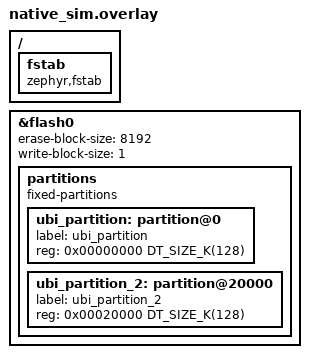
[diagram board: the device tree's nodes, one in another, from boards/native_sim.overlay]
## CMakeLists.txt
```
cmake_minimum_required(VERSION 3.20.0)

find_package(Zephyr REQUIRED HINTS $ENV{ZEPHYR_BASE})

project(ubi_tests)

target_compile_options(app PRIVATE
    -Werror
    -Wextra
    -Wshadow
    -Wdouble-promotion
    -Wformat=2
    -Wnull-dereference
    -Wunused
    -Wno-unused-parameter
)
target_compile_definitions(app PRIVATE _POSIX_C_SOURCE=200809L)

target_sources(app PRIVATE
               src/plain/tests_ubi_device.c
               src/plain/tests_ubi_volumes.c
               src/plain/tests_ubi_map_unmap.c
               src/plain/tests_ubi_write_read.c
               src/plain/tests_ubi_partial_write.c
               src/plain/tests_ubi_erase.c
               src/plain/tests_ubi_mixed.c
               src/plain/tests_ubi_error_handling.c
               src/plain/tests_ubi_error_handling_leb.c
               src/plain/tests_ubi_error_handling_volume.c
               src/plain/tests_ubi_boundary.c
               src/plain/tests_ubi_recovery.c
               src/plain/tests_ubi_recovery_reserved.c
               src/plain/tests_ubi_fault_injection.c
               src/plain/tests_ubi_io_faults.c
               src/plain/tests_ubi_init_errors.c
               src/plain/tests_ubi_init_errors_geometry.c
               src/plain/tests_ubi_hil_smoke.c
               src/plain/tests_ubi_concurrency.c
               src/plain/tests_ubi_erased_val.c
               src/plain/tests_ubi_mutation_gate.c
               src/plain/tests_ubi_vol_id_watermark.c
               src/plain/tests_ubi_io_defensive.c)

if(CONFIG_FLASH_SIMULATOR)
    target_sources(app PRIVATE src/plain/tests_ubi_stress.c
                               src/plain/tests_ubi_torture.c
                               src/plain/tests_ubi_stress_longrun.c)
endif()

target_include_directories(app PRIVATE src/common)
target_include_directories(app PRIVATE src/secure)
target_include_directories(app PRIVATE ../lib/src/plain)

target_sources(app PRIVATE src/common/arrays.c)

if(CONFIG_UBI_SECURE)
    target_include_directories(app PRIVATE ../lib/src/secure)
    target_include_directories(app PRIVATE ../lib/src/plain)
    target_sources(app PRIVATE src/secure/tests_ubi_secure_api.c
                               src/secure/tests_ubi_secure_attach.c
                               src/secure/tests_ubi_secure_device.c
                               src/secure/tests_ubi_secure_volumes.c
                               src/secure/tests_ubi_secure_write_read.c
                               src/secure/tests_ubi_secure_map_unmap.c
                               src/secure/tests_ubi_secure_erase.c
                               src/secure/tests_ubi_secure_mixed.c
                               src/secure/tests_ubi_secure_tamper.c
                               src/secure/tests_ubi_secure_runtime_policy.c
                               src/secure/tests_ubi_secure_runtime_policy_budgets.c
                               src/secure/tests_ubi_secure_recovery.c
                               src/secure/tests_ubi_secure_forensic.c
                               src/secure/tests_ubi_secure_error_handling.c
                               src/secure/tests_ubi_secure_error_handling_volume.c
                               src/secure/tests_ubi_secure_error_handling_leb.c
                               src/secure/tests_ubi_secure_fault_injection.c
                               src/secure/tests_ubi_secure_mutation_gate.c
                               src/secure/tests_ubi_secure_vol_id_watermark.c
                               src/secure/tests_ubi_secure_crypto_faults.c
                               src/secure/tests_ubi_secure_coverage.c
                               src/secure/tests_ubi_secure_defensive.c
                               src/secure/tests_ubi_secure_defensive_io_hooks.c
                               src/secure/tests_ubi_secure_defensive_reserved.c
                               src/secure/tests_ubi_secure_replay.c
                               src/secure/tests_ubi_secure_anchor.c)
    if(CONFIG_FLASH_SIMULATOR)
        target_sources(app PRIVATE src/secure/tests_ubi_secure_concurrency.c
                                   src/secure/tests_ubi_secure_stress.c)
    endif()
    # Coexistence test requires a second flash partition labelled
    # `ubi_partition_2` in the active devicetree (provided by native_sim
    # overlays, absent on HW boards).
    dt_nodelabel(ubi_part2_path NODELABEL "ubi_partition_2")
    if(DEFINED ubi_part2_path)
        target_sources(app PRIVATE src/secure/tests_ubi_secure_coexistence.c)
    endif()
    if(CONFIG_UBI_SECURE_LEB_CHUNKED)
        target_sources(app PRIVATE src/secure/tests_ubi_secure_chunked.c)
    endif()
endif()
```

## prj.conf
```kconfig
CONFIG_ZTEST=y

# Memory settings
CONFIG_HEAP_MEM_POOL_SIZE=16384
CONFIG_ZTEST_STACK_SIZE=32768

# Shell settings
CONFIG_SHELL=y
CONFIG_SHELL_VT100_COLORS=n

# Flash settings
CONFIG_FLASH=y
CONFIG_FLASH_MAP=y
CONFIG_FLASH_PAGE_LAYOUT=y
CONFIG_MPU_ALLOW_FLASH_WRITE=y

# CRC settings
CONFIG_CRC=y

# Debug and assert settings
CONFIG_DEBUG_OPTIMIZATIONS=y
CONFIG_ASSERT=y

# Log settings
CONFIG_LOG=y

# Assertion settings
CONFIG_ASSERT=y
CONFIG_ASSERT_ON_ERRORS=y

# Stats settings (required for flash simulator thresholds)
CONFIG_STATS=y
CONFIG_STATS_NAMES=y

# Heap settings
CONFIG_SYS_HEAP_RUNTIME_STATS=y

# UBI settings
CONFIG_UBI_ENABLE=y
CONFIG_UBI_LOG_LEVEL_ERR=y
CONFIG_UBI_TEST_API_ENABLE=y
CONFIG_UBI_TEST_FAULT_INJECTION=y
```

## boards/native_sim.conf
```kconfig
CONFIG_FLASH_SIMULATOR=y
CONFIG_FLASH_SIMULATOR_DOUBLE_WRITES=y
CONFIG_FLASH_SIMULATOR_EXPLICIT_ERASE=y
CONFIG_FLASH_SIMULATOR_STATS=y
```

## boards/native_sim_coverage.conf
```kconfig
# Coverage-specific configuration for native_sim
# Use with: west build -b native_sim -- -DOVERLAY_CONFIG="boards/native_sim_coverage.conf"

CONFIG_COVERAGE=y
CONFIG_COVERAGE_GCOV=y
CONFIG_COVERAGE_DUMP=y
```

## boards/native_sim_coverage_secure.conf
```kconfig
# Secure backend + coverage configuration for native_sim
CONFIG_COVERAGE=y
CONFIG_COVERAGE_GCOV=y
CONFIG_COVERAGE_DUMP=y

# Platform entropy (native_sim uses fake entropy for testing)
CONFIG_ENTROPY_GENERATOR=y
CONFIG_TEST_RANDOM_GENERATOR=y
CONFIG_ENTROPY_INIT_PRIORITY=30
CONFIG_MBEDTLS_ENTROPY_POLL_ZEPHYR=y

# PSA Crypto prerequisites (PSA_WANT_* auto-selected by UBI_SECURE)
CONFIG_MBEDTLS=y
CONFIG_MBEDTLS_PSA_CRYPTO_C=y

# UBI secure backend
CONFIG_UBI_SECURE=y
CONFIG_UBI_SECURE_TEST_FAULT_INJECTION=y

# Two concurrent devices needed by the plain+secure coexistence test.
CONFIG_UBI_MAX_NR_OF_DEVICES=2

# Lower budget thresholds for integration tests.
# Must match native_sim_secure.conf so the runtime_policy budget tests
# (which use BUDGET_HEADROOM=5) trip at the expected counter values.
CONFIG_UBI_SECURE_LEB_WRITE_BUDGET=100
CONFIG_UBI_SECURE_LEB_TOTAL_AUTH_BYTES_BUDGET=10000
CONFIG_UBI_SECURE_METADATA_COUNTER_BUDGET=100
CONFIG_UBI_SECURE_METADATA_TOTAL_AUTH_BYTES_BUDGET=10000
```

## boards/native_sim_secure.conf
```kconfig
# Secure backend configuration for native_sim
CONFIG_FLASH_SIMULATOR=y
CONFIG_FLASH_SIMULATOR_DOUBLE_WRITES=y
CONFIG_FLASH_SIMULATOR_EXPLICIT_ERASE=y
CONFIG_FLASH_SIMULATOR_STATS=y

# Platform entropy (native_sim uses fake entropy for testing)
CONFIG_ENTROPY_GENERATOR=y
CONFIG_TEST_RANDOM_GENERATOR=y
CONFIG_ENTROPY_INIT_PRIORITY=30
CONFIG_MBEDTLS_ENTROPY_POLL_ZEPHYR=y

# PSA Crypto prerequisites (PSA_WANT_* auto-selected by UBI_SECURE)
CONFIG_MBEDTLS=y
CONFIG_MBEDTLS_PSA_CRYPTO_C=y

# UBI secure backend
CONFIG_UBI_SECURE=y
CONFIG_UBI_SECURE_TEST_FAULT_INJECTION=y

# Two concurrent devices needed by the plain+secure coexistence test.
CONFIG_UBI_MAX_NR_OF_DEVICES=2

# Lower budget thresholds for integration tests (§14.5 budget test).
CONFIG_UBI_SECURE_LEB_WRITE_BUDGET=100
CONFIG_UBI_SECURE_LEB_TOTAL_AUTH_BYTES_BUDGET=10000
CONFIG_UBI_SECURE_METADATA_COUNTER_BUDGET=100
CONFIG_UBI_SECURE_METADATA_TOTAL_AUTH_BYTES_BUDGET=10000
```

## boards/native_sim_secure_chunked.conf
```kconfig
# Secure backend configuration for native_sim with chunked LEB mode
CONFIG_FLASH_SIMULATOR=y
CONFIG_FLASH_SIMULATOR_DOUBLE_WRITES=y
CONFIG_FLASH_SIMULATOR_EXPLICIT_ERASE=y
CONFIG_FLASH_SIMULATOR_STATS=y

# Platform entropy (native_sim uses fake entropy for testing)
CONFIG_ENTROPY_GENERATOR=y
CONFIG_TEST_RANDOM_GENERATOR=y
CONFIG_ENTROPY_INIT_PRIORITY=30
CONFIG_MBEDTLS_ENTROPY_POLL_ZEPHYR=y

# PSA Crypto prerequisites (PSA_WANT_* auto-selected by UBI_SECURE)
CONFIG_MBEDTLS=y
CONFIG_MBEDTLS_PSA_CRYPTO_C=y

# UBI secure backend
CONFIG_UBI_SECURE=y
CONFIG_UBI_SECURE_TEST_FAULT_INJECTION=y

# Two concurrent devices needed by the plain+secure coexistence test.
CONFIG_UBI_MAX_NR_OF_DEVICES=2

# Lower budget thresholds for integration tests (§14.5 budget test).
CONFIG_UBI_SECURE_LEB_WRITE_BUDGET=100
CONFIG_UBI_SECURE_LEB_TOTAL_AUTH_BYTES_BUDGET=10000
CONFIG_UBI_SECURE_METADATA_COUNTER_BUDGET=100
CONFIG_UBI_SECURE_METADATA_TOTAL_AUTH_BYTES_BUDGET=10000

# Chunked LEB mode with 256-byte chunks (§7.8, §15.3)
CONFIG_UBI_SECURE_LEB_CHUNKED=y
CONFIG_UBI_SECURE_LEB_CHUNK_SIZE=256
```

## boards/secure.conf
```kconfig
# Secure backend configuration for cross-build targets.
# Cross-builds are compile-only (no execution), so a test entropy source
# is acceptable where hardware entropy requires IPC (e.g. nRF5340 rng_hci).
CONFIG_TEST_RANDOM_GENERATOR=y
CONFIG_ENTROPY_GENERATOR=y
CONFIG_MBEDTLS=y
CONFIG_MBEDTLS_PSA_CRYPTO_C=y
CONFIG_MBEDTLS_ENTROPY_POLL_ZEPHYR=y
CONFIG_UBI_SECURE=y
CONFIG_UBI_SECURE_TEST_FAULT_INJECTION=y

# Lower budget thresholds for integration tests (§14.5 budget test).
CONFIG_UBI_SECURE_LEB_WRITE_BUDGET=100
CONFIG_UBI_SECURE_LEB_TOTAL_AUTH_BYTES_BUDGET=10000
CONFIG_UBI_SECURE_METADATA_COUNTER_BUDGET=100
CONFIG_UBI_SECURE_METADATA_TOTAL_AUTH_BYTES_BUDGET=10000

# PSA Crypto (mbedTLS) requires more stack on Cortex-M than the default 1 KiB.
CONFIG_MAIN_STACK_SIZE=8192
```

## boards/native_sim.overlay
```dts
/ {
	fstab {
		compatible = "zephyr,fstab";
	};
};

&flash0 {
	/* Default native_sim geometry: 8 KB erase pages, 1-byte write granularity.
	 * 16 PEBs × 8 KB = 128 KB partition (14 data + 2 reserved).
	 * For MCU-specific geometries use native_sim_nrf5340.overlay or
	 * native_sim_stm32u5.overlay via -DDTC_OVERLAY_FILE.
	 */
	erase-block-size = <8192>;
	write-block-size = <1>;

	partitions {
		compatible = "fixed-partitions";
		#address-cells = <1>;
		#size-cells = <1>;

		ubi_partition: partition@0 {
			label = "ubi_partition";
			reg = <0x00000000 DT_SIZE_K(128)>;
		};

		ubi_partition_2: partition@20000 {
			label = "ubi_partition_2";
			reg = <0x00020000 DT_SIZE_K(128)>;
		};
	};
};
```

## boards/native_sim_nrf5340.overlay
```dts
/ {
	fstab {
		compatible = "zephyr,fstab";
	};
};

&flash0 {
	/* nRF5340 geometry: 4 KB erase pages, 4-byte write alignment.
	 * 16 PEBs × 4 KB = 64 KB partition (14 data + 2 reserved).
	 */
	erase-block-size = <4096>;
	write-block-size = <4>;

	partitions {
		compatible = "fixed-partitions";
		#address-cells = <1>;
		#size-cells = <1>;

		ubi_partition: partition@0 {
			label = "ubi_partition";
			reg = <0x00000000 DT_SIZE_K(64)>;
		};

		ubi_partition_2: partition@10000 {
			label = "ubi_partition_2";
			reg = <0x00010000 DT_SIZE_K(64)>;
		};
	};
};
```

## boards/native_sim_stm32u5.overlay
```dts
/ {
	fstab {
		compatible = "zephyr,fstab";
	};
};

&flash0 {
	/* STM32U5 geometry: 8 KB erase pages, 16-byte write alignment.
	 * 16 PEBs × 8 KB = 128 KB partition (14 data + 2 reserved).
	 */
	erase-block-size = <8192>;
	write-block-size = <16>;

	partitions {
		compatible = "fixed-partitions";
		#address-cells = <1>;
		#size-cells = <1>;

		ubi_partition: partition@0 {
			label = "ubi_partition";
			reg = <0x00000000 DT_SIZE_K(128)>;
		};

		ubi_partition_2: partition@20000 {
			label = "ubi_partition_2";
			reg = <0x00020000 DT_SIZE_K(128)>;
		};
	};
};
```

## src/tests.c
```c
/**
 * \file    tests.c
 * \author  Kamil Kielbasa
 * \brief   Hardware tests for Unsorted Block Images (UBI) implementation.
 * \version 0.1
 * \date    2025-07-25
 *
 * \copyright Copyright (c) 2025
 *
 */

/* Include files ----------------------------------------------------------- */

/* UBI header: */
#include <ubi.h>

/* Zephyr headers: */
#include <zephyr/ztest.h>
#include <zephyr/device.h>
#include <zephyr/drivers/flash.h>
#include <zephyr/kernel.h>
#include <zephyr/storage/flash_map.h>
#include <zephyr/sys/printk.h>
#include <zephyr/toolchain/common.h>
#include <zephyr/sys/sys_heap.h>

#include <stdio.h>
#include <stdint.h>
#include <stddef.h>

/* Module defines ---------------------------------------------------------- */

#define UBI_PARTITION_NAME ubi_partition
#define UBI_PARTITION_DEVICE FIXED_PARTITION_DEVICE(UBI_PARTITION_NAME)
#define UBI_PARTITION_OFFSET FIXED_PARTITION_OFFSET(UBI_PARTITION_NAME)
#define UBI_PARTITION_SIZE FIXED_PARTITION_SIZE(UBI_PARTITION_NAME)

/* Module types and type definitiones -------------------------------------- */
/* Module interface variables and constants -------------------------------- */
/* Static variables and constants ------------------------------------------ */

static struct mem_tech_device mtd = { 0 };

#if defined(CONFIG_SYS_HEAP_RUNTIME_STATS)
extern struct sys_heap _system_heap;
#endif

static const uint8_t rdata[256] = {
	0x00, 0x01, 0x02, 0x03, 0x04, 0x05, 0x06, 0x07, 0x08, 0x09, 0x0A, 0x0B, 0x0C, 0x0D, 0x0E,
	0x0F, 0x10, 0x11, 0x12, 0x13, 0x14, 0x15, 0x16, 0x17, 0x18, 0x19, 0x1A, 0x1B, 0x1C, 0x1D,
	0x1E, 0x1F, 0x20, 0x21, 0x22, 0x23, 0x24, 0x25, 0x26, 0x27, 0x28, 0x29, 0x2A, 0x2B, 0x2C,
	0x2D, 0x2E, 0x2F, 0x30, 0x31, 0x32, 0x33, 0x34, 0x35, 0x36, 0x37, 0x38, 0x39, 0x3A, 0x3B,
	0x3C, 0x3D, 0x3E, 0x3F, 0x40, 0x41, 0x42, 0x43, 0x44, 0x45, 0x46, 0x47, 0x48, 0x49, 0x4A,
	0x4B, 0x4C, 0x4D, 0x4E, 0x4F, 0x50, 0x51, 0x52, 0x53, 0x54, 0x55, 0x56, 0x57, 0x58, 0x59,
	0x5A, 0x5B, 0x5C, 0x5D, 0x5E, 0x5F, 0x60, 0x61, 0x62, 0x63, 0x64, 0x65, 0x66, 0x67, 0x68,
	0x69, 0x6A, 0x6B, 0x6C, 0x6D, 0x6E, 0x6F, 0x70, 0x71, 0x72, 0x73, 0x74, 0x75, 0x76, 0x77,
	0x78, 0x79, 0x7A, 0x7B, 0x7C, 0x7D, 0x7E, 0x7F, 0x80, 0x81, 0x82, 0x83, 0x84, 0x85, 0x86,
	0x87, 0x88, 0x89, 0x8A, 0x8B, 0x8C, 0x8D, 0x8E, 0x8F, 0x90, 0x91, 0x92, 0x93, 0x94, 0x95,
	0x96, 0x97, 0x98, 0x99, 0x9A, 0x9B, 0x9C, 0x9D, 0x9E, 0x9F, 0xA0, 0xA1, 0xA2, 0xA3, 0xA4,
	0xA5, 0xA6, 0xA7, 0xA8, 0xA9, 0xAA, 0xAB, 0xAC, 0xAD, 0xAE, 0xAF, 0xB0, 0xB1, 0xB2, 0xB3,
	0xB4, 0xB5, 0xB6, 0xB7, 0xB8, 0xB9, 0xBA, 0xBB, 0xBC, 0xBD, 0xBE, 0xBF, 0xC0, 0xC1, 0xC2,
	0xC3, 0xC4, 0xC5, 0xC6, 0xC7, 0xC8, 0xC9, 0xCA, 0xCB, 0xCC, 0xCD, 0xCE, 0xCF, 0xD0, 0xD1,
	0xD2, 0xD3, 0xD4, 0xD5, 0xD6, 0xD7, 0xD8, 0xD9, 0xDA, 0xDB, 0xDC, 0xDD, 0xDE, 0xDF, 0xE0,
	0xE1, 0xE2, 0xE3, 0xE4, 0xE5, 0xE6, 0xE7, 0xE8, 0xE9, 0xEA, 0xEB, 0xEC, 0xED, 0xEE, 0xEF,
	0xF0, 0xF1, 0xF2, 0xF3, 0xF4, 0xF5, 0xF6, 0xF7, 0xF8, 0xF9, 0xFA, 0xFB, 0xFC, 0xFD, 0xFE,
	0xFF
};

/* Static function declarations -------------------------------------------- */

static void *ztest_suite_setup(void);
static void ztest_suite_after(void *ctx);

static void ztest_testcase_before(void *ctx);
static void ztest_testcase_teardown(void *ctx);

/* Static function definitions --------------------------------------------- */

static void *ztest_suite_setup(void)
{
	const struct device *flash_dev = UBI_PARTITION_DEVICE;
	zassert_true(device_is_ready(flash_dev));

	struct flash_pages_info page_info = { 0 };
	zassert_ok(flash_get_page_info_by_offs(flash_dev, 0, &page_info));

	const size_t write_block_size = flash_get_write_block_size(flash_dev);
	const size_t erase_block_size = page_info.size;

	mtd.dev = flash_dev;
	mtd.p_off = UBI_PARTITION_OFFSET;
	mtd.p_size = UBI_PARTITION_SIZE;
	mtd.eb_size = erase_block_size;
	mtd.wb_size = write_block_size;

	return NULL;
}

static void ztest_suite_after(void *ctx)
{
	(void)ctx;

	return;
}

static void ztest_testcase_before(void *ctx)
{
	(void)ctx;

	zassert_ok(flash_erase(UBI_PARTITION_DEVICE, UBI_PARTITION_OFFSET, UBI_PARTITION_SIZE));

	return;
}

static void ztest_testcase_teardown(void *ctx)
{
	(void)ctx;
	return;
}

/* Module interface function definitions ----------------------------------- */

ZTEST_SUITE(ubi, NULL, ztest_suite_setup, ztest_testcase_before, ztest_testcase_teardown,
	    ztest_suite_after);

ZTEST(ubi, init_deinit)
{
	zassert_ok(ubi_init(&mtd));

	struct ubi_device_info dev_info = { 0 };
	zassert_ok(ubi_info(&dev_info, NULL));

	zassert_equal(0, dev_info.alloc_pebs);
	zassert_equal(0, dev_info.dirty_pebs);
	zassert_equal(0, dev_info.bad_pebs);
	zassert_not_equal(0, dev_info.free_pebs);

	const size_t nr_of_pebs = mtd.p_size / mtd.eb_size;
	zassert_not_equal(0, dev_info.leb_count);
	zassert_not_equal(nr_of_pebs, dev_info.leb_count);

	zassert_not_equal(0, dev_info.leb_size);
	zassert_not_equal(mtd.eb_size, dev_info.leb_size);

	zassert_ok(ubi_deinit());
}

ZTEST(ubi, multiple_init_deinit)
{
	zassert_ok(ubi_init(&mtd));
	zassert_ok(ubi_deinit());
	zassert_ok(ubi_init(&mtd));
	zassert_ok(ubi_deinit());
	zassert_ok(ubi_init(&mtd));
	zassert_ok(ubi_deinit());
}

ZTEST(ubi, init_deinit_with_heap_checks)
{
	struct sys_memory_stats stat_before_init = { 0 };
	zassert_ok(sys_heap_runtime_stats_get(&_system_heap, &stat_before_init));

	zassert_ok(ubi_init(&mtd));

	struct sys_memory_stats stat_after_init = { 0 };
	zassert_ok(sys_heap_runtime_stats_get(&_system_heap, &stat_after_init));

	zassert_ok(ubi_deinit());

	struct sys_memory_stats stat_after_deinit = { 0 };
	zassert_ok(sys_heap_runtime_stats_get(&_system_heap, &stat_after_deinit));

	zassert_equal(stat_before_init.free_bytes, stat_after_deinit.free_bytes);
	zassert_equal(stat_before_init.allocated_bytes, stat_after_deinit.allocated_bytes);
	zassert_equal(stat_before_init.max_allocated_bytes, stat_after_deinit.max_allocated_bytes);

	zassert_not_equal(stat_after_init.free_bytes, stat_after_deinit.free_bytes);
	zassert_not_equal(stat_after_init.allocated_bytes, stat_after_deinit.allocated_bytes);
	zassert_equal(stat_after_init.max_allocated_bytes, stat_after_deinit.max_allocated_bytes);
}

ZTEST(ubi, map_and_unmap)
{
	zassert_ok(ubi_init(&mtd));

	struct ubi_device_info dev_info = { 0 };
	zassert_ok(ubi_info(&dev_info, NULL));

	for (size_t lnum = 0; lnum < dev_info.leb_count; ++lnum) {
		zassert_ok(ubi_leb_map(lnum));
	}

	zassert_ok(ubi_info(&dev_info, NULL));
	zassert_equal(dev_info.leb_count, dev_info.alloc_pebs);
	zassert_equal(0, dev_info.free_pebs);
	zassert_equal(0, dev_info.dirty_pebs);
	zassert_equal(0, dev_info.bad_pebs);

	for (size_t lnum = 0; lnum < dev_info.leb_count; ++lnum) {
		zassert_ok(ubi_leb_unmap(lnum));
	}

	zassert_ok(ubi_info(&dev_info, NULL));
	zassert_equal(0, dev_info.alloc_pebs);
	zassert_equal(0, dev_info.free_pebs);
	zassert_equal(dev_info.leb_count, dev_info.dirty_pebs);
	zassert_equal(0, dev_info.bad_pebs);

	zassert_ok(ubi_deinit());
}

ZTEST(ubi, map_unmap_erase_map)
{
	zassert_ok(ubi_init(&mtd));

	struct ubi_device_info dev_info = { 0 };
	zassert_ok(ubi_info(&dev_info, NULL));

	for (size_t lnum = 0; lnum < dev_info.leb_count; ++lnum) {
		zassert_ok(ubi_leb_map(lnum));
	}

	zassert_ok(ubi_info(&dev_info, NULL));
	zassert_equal(dev_info.leb_count, dev_info.alloc_pebs);
	zassert_equal(0, dev_info.free_pebs);
	zassert_equal(0, dev_info.dirty_pebs);
	zassert_equal(0, dev_info.bad_pebs);

	for (size_t lnum = 0; lnum < dev_info.leb_count; ++lnum) {
		zassert_ok(ubi_leb_unmap(lnum));
	}

	zassert_ok(ubi_info(&dev_info, NULL));
	zassert_equal(0, dev_info.alloc_pebs);
	zassert_equal(0, dev_info.free_pebs);
	zassert_equal(dev_info.leb_count, dev_info.dirty_pebs);
	zassert_equal(0, dev_info.bad_pebs);

	while (dev_info.dirty_pebs > 0) {
		zassert_ok(ubi_peb_erase());
		zassert_ok(ubi_info(&dev_info, NULL));
	}

	zassert_ok(ubi_info(&dev_info, NULL));
	zassert_equal(0, dev_info.alloc_pebs);
	zassert_equal(dev_info.leb_count, dev_info.free_pebs);
	zassert_equal(0, dev_info.dirty_pebs);
	zassert_equal(0, dev_info.bad_pebs);

	for (size_t lnum = 0; lnum < dev_info.leb_count; ++lnum) {
		zassert_ok(ubi_leb_map(lnum));
	}

	zassert_ok(ubi_info(&dev_info, NULL));
	zassert_equal(dev_info.leb_count, dev_info.alloc_pebs);
	zassert_equal(0, dev_info.free_pebs);
	zassert_equal(0, dev_info.dirty_pebs);
	zassert_equal(0, dev_info.bad_pebs);

	zassert_ok(ubi_deinit());
}

ZTEST(ubi, write_read_small_buffer)
{
	zassert_ok(ubi_init(&mtd));

	const uint8_t buf[32] = { 0x00, 0x11, 0x22, 0x33, 0x44, 0x55, 0x66, 0x77, 0x88, 0x99, 0xAA,
				  0xBB, 0xCC, 0xDD, 0xEE, 0xFF, 0x1A, 0x2B, 0x3C, 0x4D, 0x5E, 0x6F,
				  0x70, 0x81, 0x92, 0xA3, 0xB4, 0xC5, 0xD6, 0xE7, 0xF8, 0x09 };

	const size_t lnum = 0;
	zassert_ok(ubi_leb_write(lnum, buf, ARRAY_SIZE(buf)));

	const size_t offset = 0;

	size_t len = 0;
	uint8_t output[ARRAY_SIZE(buf)] = { 0 };
	zassert_ok(ubi_leb_read(lnum, output, offset, &len));

	zassert_equal(ARRAY_SIZE(buf), len);
	zassert_mem_equal(buf, output, ARRAY_SIZE(buf), "Memory blocks are not equal");

	zassert_ok(ubi_deinit());
}

ZTEST(ubi, write_read_max_buffer)
{
	zassert_ok(ubi_init(&mtd));

	struct ubi_device_info dev_info = { 0 };
	zassert_ok(ubi_info(&dev_info, NULL));

	uint8_t buf[dev_info.leb_size];
	memset(buf, 0, sizeof(buf));

	for (size_t i = 0; i < ARRAY_SIZE(buf); ++i)
		buf[i] = (uint8_t)i;

	const size_t lnum = dev_info.leb_count - 1;
	zassert_ok(ubi_leb_write(lnum, buf, ARRAY_SIZE(buf)));

	const size_t offset = 0;

	size_t len = 0;
	uint8_t output[dev_info.leb_size];
	memset(output, 0, sizeof(output));
	zassert_ok(ubi_leb_read(lnum, output, offset, &len));

	zassert_equal(ARRAY_SIZE(buf), len);
	zassert_mem_equal(buf, output, ARRAY_SIZE(buf), "Memory blocks are not equal");

	zassert_ok(ubi_deinit());
}

ZTEST(ubi, full_scenario)
{
	zassert_ok(ubi_init(&mtd));

	struct ubi_device_info dev_info = { 0 };
	zassert_ok(ubi_info(&dev_info, NULL));

	const size_t map_lnums[] = { 0, 1, 2, 3, 4, 5 };

	for (size_t i = 0; i < ARRAY_SIZE(map_lnums); ++i) {
		zassert_ok(ubi_leb_map(map_lnums[i]));

		bool is_map = false;
		zassert_ok(ubi_leb_is_mapped(map_lnums[i], &is_map));
		zassert_true(is_map);
	}

	const size_t wr_lnums[] = { dev_info.leb_count / 2 + 0, dev_info.leb_count / 2 + 1,
				    dev_info.leb_count / 2 + 2, dev_info.leb_count / 2 + 3 };
	const size_t wr_sizes[] = { 32, 64, 128, 256 };

	for (size_t i = 0; i < ARRAY_SIZE(wr_lnums); ++i) {
		zassert_ok(ubi_leb_write(wr_lnums[i], rdata, wr_sizes[i]));

		bool is_map = false;
		zassert_ok(ubi_leb_is_mapped(wr_lnums[i], &is_map));
		zassert_true(is_map);
	}

	zassert_ok(ubi_info(&dev_info, NULL));
	zassert_equal(dev_info.alloc_pebs, ARRAY_SIZE(map_lnums) + ARRAY_SIZE(wr_lnums));
	zassert_equal(dev_info.free_pebs,
		      dev_info.leb_count - ARRAY_SIZE(map_lnums) - ARRAY_SIZE(wr_lnums));
	zassert_equal(0, dev_info.dirty_pebs);
	zassert_equal(0, dev_info.bad_pebs);

	for (size_t i = 0; i < ARRAY_SIZE(map_lnums); ++i) {
		const size_t offset = 0;
		uint8_t buf[ARRAY_SIZE(rdata)] = { 0 };
		size_t len = 0;

		zassert_ok(ubi_leb_read(map_lnums[i], buf, offset, &len));
		zassert_equal(0, len);
	}

	for (size_t i = 0; i < ARRAY_SIZE(wr_lnums); ++i) {
		const size_t offset = 0;
		uint8_t buf[ARRAY_SIZE(rdata)] = { 0 };
		size_t len = 0;

		zassert_ok(ubi_leb_read(wr_lnums[i], buf, offset, &len));
		zassert_equal(wr_sizes[i], len);
		zassert_mem_equal(rdata, buf, len, "Memory blocks are not equal");
	}

	zassert_ok(ubi_deinit());
}

ZTEST(ubi, flash_equal_weariness)
{
	size_t reserved_pebs = 0;
	struct ubi_device_info dev_info = { 0 };
	struct ubi_flash_info flash_info = { 0 };

	zassert_ok(ubi_init(&mtd));

	const size_t cycles = 5;
	const size_t cycle_exp_peb_ec[] = { 0, 1, 2, 3, 4 };
	const size_t cycle_exp_ec_avr[] = { 0, 1, 2, 3, 4 };

	/* Cycle 1: */
	for (size_t cycle = 0; cycle < cycles; ++cycle) {
		zassert_ok(ubi_info(&dev_info, &flash_info));
		zassert_equal(cycle_exp_ec_avr[cycle], flash_info.ec_average);
		zassert_not_equal(0, flash_info.peb_count);

		for (size_t pnum = 0; pnum < flash_info.peb_count; ++pnum) {
			if (flash_info.peb_init[pnum]) {
				zassert_equal(cycle_exp_peb_ec[cycle], flash_info.peb_ec[pnum]);
			} else {
				reserved_pebs += 1;
			}
		}
		zassert_equal(1, reserved_pebs);

		k_free(flash_info.peb_init);
		k_free(flash_info.peb_ec);

		for (size_t lnum = 0; lnum < dev_info.leb_count; ++lnum) {
			zassert_ok(ubi_leb_map(lnum));
			zassert_ok(ubi_leb_unmap(lnum));
			zassert_ok(ubi_peb_erase());
		}

		memset(&dev_info, 0, sizeof(dev_info));
		memset(&flash_info, 0, sizeof(flash_info));
		reserved_pebs = 0;
	}

	zassert_ok(ubi_deinit());
}
```

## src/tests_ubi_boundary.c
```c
/**
 * \file    tests_ubi_boundary.c
 *
 * \author  Kamil Kielbasa
 *
 * \brief   Tests for UBI LEB boundary and capacity edge cases.
 *
 * \version 0.9
 * \date    2026-03-26
 *
 * \copyright Copyright (c) 2025
 *
 */

/* Include files ------------------------------------------------------------------------------- */

/* UBI header: */
#include <ubi.h>

/* Zephyr headers: */
#include <zephyr/ztest.h>
#include <zephyr/device.h>
#include <zephyr/drivers/flash.h>
#include <zephyr/kernel.h>
#include <zephyr/storage/flash_map.h>
#include <zephyr/sys/printk.h>
#include <zephyr/toolchain/common.h>
#include <zephyr/sys/sys_heap.h>

#include <stdio.h>
#include <stdint.h>
#include <stddef.h>
#include <string.h>

/* Module defines ------------------------------------------------------------------------------ */

#define UBI_PARTITION_NAME ubi_partition
#define UBI_PARTITION_DEVICE FIXED_PARTITION_DEVICE(UBI_PARTITION_NAME)
#define UBI_PARTITION_OFFSET FIXED_PARTITION_OFFSET(UBI_PARTITION_NAME)
#define UBI_PARTITION_SIZE FIXED_PARTITION_SIZE(UBI_PARTITION_NAME)

/* UBI header sizes (must match lib/src/ubi_io.h). */
#define UBI_EC_HDR_SIZE (16)
#define UBI_VID_HDR_SIZE (32)

/* Module types and type definitiones ---------------------------------------------------------- */
/* Module interface variables and constants ---------------------------------------------------- */
/* Static variables and constants -------------------------------------------------------------- */

static struct ubi_mtd mtd = { 0 };

/* Static function declarations ---------------------------------------------------------------- */

static void *ztest_suite_setup(void);
static void ztest_suite_after(void *ctx);

static void ztest_testcase_before(void *ctx);
static void ztest_testcase_teardown(void *ctx);

/* Static function definitions ----------------------------------------------------------------- */

static void *ztest_suite_setup(void)
{
	const struct device *flash_dev = UBI_PARTITION_DEVICE;
	zassert_true(device_is_ready(flash_dev));

	struct flash_pages_info page_info = { 0 };
	zassert_ok(flash_get_page_info_by_offs(flash_dev, 0, &page_info));

	const size_t write_block_size = flash_get_write_block_size(flash_dev);
	const size_t erase_block_size = page_info.size;

	mtd.partition_id = FIXED_PARTITION_ID(UBI_PARTITION_NAME);
	mtd.erase_block_size = erase_block_size;
	mtd.write_block_size = write_block_size;

	return NULL;
}

static void ztest_suite_after(void *ctx)
{
	(void)ctx;

	return;
}

static void ztest_testcase_before(void *ctx)
{
	(void)ctx;

	zassert_ok(flash_erase(UBI_PARTITION_DEVICE, UBI_PARTITION_OFFSET, UBI_PARTITION_SIZE));

	return;
}

static void ztest_testcase_teardown(void *ctx)
{
	(void)ctx;
	return;
}

/* Module interface function definitions ------------------------------------------------------- */

ZTEST_SUITE(ubi_boundary, NULL, ztest_suite_setup, ztest_testcase_before, ztest_testcase_teardown,
	    ztest_suite_after);

/**
 * \brief Verify that writing exactly the maximum LEB data capacity succeeds.
 *
 * \details Scenario: Create a dynamic volume with 2 LEBs. Calculate the maximum
 *          writable data per LEB (erase_block_size - EC_HDR - VID_HDR = 8144 bytes
 *          on 8 KB erase blocks). Fill a buffer with a 0xAB pattern of exactly that
 *          size and write it to LEB 0.
 *
 * \expect The write succeeds. The stored size equals the maximum data capacity.
 *         Reading back the full LEB returns identical data byte-for-byte.
 */
ZTEST(ubi_boundary, write_max_leb_data)
{
	struct ubi_device *ubi = NULL;
	zassert_ok(ubi_device_init(&mtd, &ubi));

	const struct ubi_volume_config cfg = {
		.name = "max_leb",
		.type = UBI_VOLUME_TYPE_DYNAMIC,
		.leb_count = 2,
	};
	int vol_id;
	zassert_ok(ubi_volume_create(ubi, &cfg, &vol_id));

	const size_t max_data = mtd.erase_block_size - UBI_EC_HDR_SIZE - UBI_VID_HDR_SIZE;
	uint8_t *wbuf = k_malloc(max_data);
	zassert_not_null(wbuf);
	memset(wbuf, 0xAB, max_data);

	/* Write exactly max capacity — must succeed. */
	zassert_ok(ubi_leb_write(ubi, vol_id, 0, wbuf, max_data));
	k_free(wbuf);

	/* Read back and verify. */
	uint8_t *rbuf = k_malloc(max_data);
	zassert_not_null(rbuf);
	memset(rbuf, 0, max_data);

	size_t stored_size = 0;
	zassert_ok(ubi_leb_get_size(ubi, vol_id, 0, &stored_size));
	zassert_equal(stored_size, max_data);

	zassert_ok(ubi_leb_read(ubi, vol_id, 0, 0, rbuf, max_data));

	/* Verify all bytes are 0xAB */
	bool all_match = true;
	for (size_t i = 0; i < max_data; i++) {
		if (rbuf[i] != 0xAB) {
			all_match = false;
			break;
		}
	}
	zassert_true(all_match, "Read-back data mismatch");

	k_free(rbuf);
	zassert_ok(ubi_device_deinit(ubi));
}

/**
 * \brief Verify that writing one byte beyond the maximum LEB capacity is rejected.
 *
 * \details Scenario: Create a dynamic volume with 2 LEBs. Attempt to write
 *          (max_data + 1) bytes to a single LEB, which exceeds the available
 *          data area after the EC and VID headers.
 *
 * \expect ubi_leb_write() returns -ENOSPC. No data is written to the LEB.
 */
ZTEST(ubi_boundary, write_exceeds_leb_capacity)
{
	struct ubi_device *ubi = NULL;
	zassert_ok(ubi_device_init(&mtd, &ubi));

	const struct ubi_volume_config cfg = {
		.name = "exceed",
		.type = UBI_VOLUME_TYPE_DYNAMIC,
		.leb_count = 2,
	};
	int vol_id;
	zassert_ok(ubi_volume_create(ubi, &cfg, &vol_id));

	const size_t max_data = mtd.erase_block_size - UBI_EC_HDR_SIZE - UBI_VID_HDR_SIZE;
	uint8_t *wbuf = k_malloc(max_data + 1);
	zassert_not_null(wbuf);
	memset(wbuf, 0xCD, max_data + 1);

	/* One byte over capacity — must fail with -ENOSPC. */
	zassert_equal(-ENOSPC, ubi_leb_write(ubi, vol_id, 0, wbuf, max_data + 1));

	k_free(wbuf);
	zassert_ok(ubi_device_deinit(ubi));
}

/**
 * \brief Verify reading at the exact end boundary of stored data.
 *
 * \details Scenario: Write an 8-byte pattern to LEB 0. Issue a read with
 *          offset=4 and size=4, so that offset + size equals exactly the
 *          stored data size (8 bytes). This tests the boundary condition
 *          where the read touches the last byte of stored data.
 *
 * \expect ubi_leb_read() succeeds. The 4 returned bytes match the tail
 *         portion (bytes 4..7) of the original pattern.
 */
ZTEST(ubi_boundary, read_at_exact_boundary)
{
	struct ubi_device *ubi = NULL;
	zassert_ok(ubi_device_init(&mtd, &ubi));

	const struct ubi_volume_config cfg = {
		.name = "rbound",
		.type = UBI_VOLUME_TYPE_DYNAMIC,
		.leb_count = 2,
	};
	int vol_id;
	zassert_ok(ubi_volume_create(ubi, &cfg, &vol_id));

	const uint8_t pattern[] = { 0x11, 0x22, 0x33, 0x44, 0x55, 0x66, 0x77, 0x88 };
	zassert_ok(ubi_leb_write(ubi, vol_id, 0, pattern, sizeof(pattern)));

	/* Read last 4 bytes using offset — offset(4) + size(4) = 8 = stored_size. */
	uint8_t tail[4] = { 0 };
	zassert_ok(ubi_leb_read(ubi, vol_id, 0, 4, tail, sizeof(tail)));
	zassert_mem_equal(tail, &pattern[4], sizeof(tail));

	zassert_ok(ubi_device_deinit(ubi));
}

/**
 * \brief Verify writes at and just above the write-block alignment boundary.
 *
 * \details Scenario: Create a dynamic volume with 2 LEBs. Write exactly 16 bytes
 *          (aligned to WRITE_BLOCK_SIZE_ALIGNMENT) to LEB 0, and 17 bytes (one
 *          byte over alignment, triggering the partial-block padding path in
 *          ubi_leb_data_write()) to LEB 1. Read both back.
 *
 * \expect Both writes succeed. Read-back data matches the original patterns
 *         exactly, confirming that the padding logic does not corrupt data.
 */
ZTEST(ubi_boundary, write_alignment_boundary)
{
	struct ubi_device *ubi = NULL;
	zassert_ok(ubi_device_init(&mtd, &ubi));

	const struct ubi_volume_config cfg = {
		.name = "align",
		.type = UBI_VOLUME_TYPE_DYNAMIC,
		.leb_count = 2,
	};
	int vol_id;
	zassert_ok(ubi_volume_create(ubi, &cfg, &vol_id));

	/* Write exactly 16 bytes (aligned) */
	uint8_t aligned[16];
	memset(aligned, 0xAA, sizeof(aligned));
	zassert_ok(ubi_leb_write(ubi, vol_id, 0, aligned, sizeof(aligned)));

	uint8_t rbuf[16] = { 0 };
	zassert_ok(ubi_leb_read(ubi, vol_id, 0, 0, rbuf, sizeof(rbuf)));
	zassert_mem_equal(aligned, rbuf, sizeof(aligned));

	/* Write 17 bytes (1 byte over alignment — exercises padding path) */
	uint8_t unaligned[17];
	memset(unaligned, 0xBB, sizeof(unaligned));
	zassert_ok(ubi_leb_write(ubi, vol_id, 1, unaligned, sizeof(unaligned)));

	uint8_t rbuf2[17] = { 0 };
	zassert_ok(ubi_leb_read(ubi, vol_id, 1, 0, rbuf2, sizeof(rbuf2)));
	zassert_mem_equal(unaligned, rbuf2, sizeof(unaligned));

	zassert_ok(ubi_device_deinit(ubi));
}

/**
 * \brief Verify writes smaller than the write-block alignment (< 16 bytes).
 *
 * \details Scenario: Create a dynamic volume with 2 LEBs. Write 1 byte (the
 *          minimum possible write) to LEB 0 and 15 bytes (just under the 16-byte
 *          alignment boundary) to LEB 1. These sizes exercise the small-buffer
 *          padding path in ubi_leb_data_write() where the data is smaller than
 *          a single alignment unit.
 *
 * \expect Both writes succeed. ubi_leb_get_size() returns the exact logical
 *         size (1 and 15). Read-back data matches the original bytes.
 */
ZTEST(ubi_boundary, write_sub_alignment)
{
	struct ubi_device *ubi = NULL;
	zassert_ok(ubi_device_init(&mtd, &ubi));

	const struct ubi_volume_config cfg = {
		.name = "sub",
		.type = UBI_VOLUME_TYPE_DYNAMIC,
		.leb_count = 2,
	};
	int vol_id;
	zassert_ok(ubi_volume_create(ubi, &cfg, &vol_id));

	/* Write 1 byte — minimum possible write */
	const uint8_t one = 0xFF;
	zassert_ok(ubi_leb_write(ubi, vol_id, 0, &one, 1));

	size_t stored = 0;
	zassert_ok(ubi_leb_get_size(ubi, vol_id, 0, &stored));
	zassert_equal(stored, 1);

	uint8_t rb = 0;
	zassert_ok(ubi_leb_read(ubi, vol_id, 0, 0, &rb, 1));
	zassert_equal(rb, 0xFF);

	/* Write 15 bytes — just under alignment */
	uint8_t buf15[15];
	memset(buf15, 0xCC, sizeof(buf15));
	zassert_ok(ubi_leb_write(ubi, vol_id, 1, buf15, sizeof(buf15)));

	uint8_t rbuf15[15] = { 0 };
	zassert_ok(ubi_leb_read(ubi, vol_id, 1, 0, rbuf15, sizeof(rbuf15)));
	zassert_mem_equal(buf15, rbuf15, sizeof(buf15));

	zassert_ok(ubi_device_deinit(ubi));
}

/* --- Sequence number monotonicity across remount --- */

/* Raw VID header for direct flash reads. */
struct raw_vid_hdr {
	uint32_t magic;
	uint8_t version;
	uint8_t padding[3];
	uint32_t lnum;
	uint32_t vol_id;
	uint64_t sqnum;
	uint32_t data_size;
	uint32_t hdr_crc;
};

/**
 * \brief Verify that global_sqnum is strictly monotonic after device re-init.
 *
 * \details Scenario: init → create volume → write LEB 0 → deinit →
 *          init → write LEB 1 → read raw VID headers of both LEBs.
 *
 * \expect The second write's sqnum is strictly greater than the first's.
 */
ZTEST(ubi_boundary, sqnum_monotonic_across_remount)
{
	/* First session: write LEB 0. */
	struct ubi_device *ubi = NULL;
	zassert_ok(ubi_device_init(&mtd, &ubi));

	const struct ubi_volume_config cfg = {
		.name = "sqn",
		.type = UBI_VOLUME_TYPE_DYNAMIC,
		.leb_count = 2,
	};
	int vol_id;
	zassert_ok(ubi_volume_create(ubi, &cfg, &vol_id));

	const uint8_t data1[] = { 0xAA };
	zassert_ok(ubi_leb_write(ubi, vol_id, 0, data1, sizeof(data1)));

	zassert_ok(ubi_device_deinit(ubi));

	/* Second session: write LEB 1. */
	ubi = NULL;
	zassert_ok(ubi_device_init(&mtd, &ubi));

	/* Re-read vol_id after remount. */
	struct ubi_volume_config cfg2;
	size_t alloc;
	zassert_ok(ubi_volume_get_info(ubi, vol_id, &cfg2, &alloc));

	const uint8_t data2[] = { 0xBB };
	zassert_ok(ubi_leb_write(ubi, vol_id, 1, data2, sizeof(data2)));

	/* Read raw VID headers to compare sqnums. */
	const struct flash_area *fa = NULL;
	zassert_ok(flash_area_open(FIXED_PARTITION_ID(ubi_partition), &fa));

	const size_t nr_of_pebs = fa->fa_size / mtd.erase_block_size;
	uint64_t sqnum_leb0 = 0;
	uint64_t sqnum_leb1 = 0;

	for (size_t p = CONFIG_UBI_DEV_HDR_NR_OF_RES_PEBS; p < nr_of_pebs; ++p) {
		struct raw_vid_hdr vid;
		zassert_ok(flash_area_read(fa, (p * mtd.erase_block_size) + UBI_EC_HDR_SIZE, &vid,
					   sizeof(vid)));

		if (vid.magic != 0x55424921)
			continue;

		if (vid.vol_id == (uint32_t)vol_id && vid.lnum == 0)
			sqnum_leb0 = vid.sqnum;
		else if (vid.vol_id == (uint32_t)vol_id && vid.lnum == 1)
			sqnum_leb1 = vid.sqnum;
	}

	flash_area_close(fa);

	zassert_true(sqnum_leb0 > 0, "LEB 0 sqnum must be non-zero");
	zassert_true(sqnum_leb1 > sqnum_leb0, "LEB 1 sqnum (%llu) must be > LEB 0 sqnum (%llu)",
		     sqnum_leb1, sqnum_leb0);

	zassert_ok(ubi_device_deinit(ubi));
}
```

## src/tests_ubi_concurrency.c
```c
/**
 * \file    tests_ubi_concurrency.c
 *
 * \brief   Multi-threaded concurrency and partition guard tests.
 *
 * Validates that the per-device mutex correctly serializes concurrent
 * operations, that deinit waits for in-flight work, and that the
 * single-handle-per-partition guard works as specified.
 *
 * \copyright Copyright (c) 2026
 */

#include <ubi.h>
#include "ubi_test_fixture.h"

#include <zephyr/ztest.h>
#include <zephyr/kernel.h>

#include <string.h>

/* -------------------------------------------------------------------------- */

static struct ubi_mtd mtd = { 0 };

static void *ztest_suite_setup(void)
{
	ubi_test_setup_mtd(&mtd);
	return NULL;
}

static void ztest_suite_after(void *ctx)
{
	(void)ctx;
}

static void ztest_testcase_before(void *ctx)
{
	(void)ctx;
	ubi_test_erase_partition();
}

static void ztest_testcase_teardown(void *ctx)
{
	(void)ctx;
}

ZTEST_SUITE(ubi_concurrency, NULL, ztest_suite_setup, ztest_testcase_before,
	    ztest_testcase_teardown, ztest_suite_after);

/* -------------------------------------------------------------------------- */

#define THREAD_STACK_SIZE 4096
#define READER_ITERATIONS 200
#define WRITER_ITERATIONS 50
#define NUM_READER_THREADS 4

static K_THREAD_STACK_ARRAY_DEFINE(reader_stacks, NUM_READER_THREADS, THREAD_STACK_SIZE);
static struct k_thread reader_threads[NUM_READER_THREADS];

static K_THREAD_STACK_DEFINE(writer_stack, THREAD_STACK_SIZE);
static struct k_thread writer_thread;

struct reader_ctx {
	struct ubi_device *ubi;
	volatile bool *stop;
	int vol_id;
};

struct writer_ctx {
	struct ubi_device *ubi;
	volatile bool *stop;
	int vol_id;
};

/* -------------------------------------------------------------------------- */

static void reader_entry(void *p1, void *p2, void *p3)
{
	struct reader_ctx *ctx = (struct reader_ctx *)p1;

	(void)p2;
	(void)p3;

	for (int i = 0; i < READER_ITERATIONS && !(*ctx->stop); i++) {
		struct ubi_device_info info = { 0 };
		int ret = ubi_device_get_info(ctx->ubi, &info);
		zassert_ok(ret);

		struct ubi_volume_config vol_cfg = { 0 };
		size_t alloc_lebs = 0;
		ret = ubi_volume_get_info(ctx->ubi, ctx->vol_id, &vol_cfg, &alloc_lebs);
		zassert_ok(ret);

		bool mapped = false;
		ret = ubi_leb_is_mapped(ctx->ubi, ctx->vol_id, 0, &mapped);
		zassert_ok(ret);
	}
}

/**
 * \brief 4 threads concurrently read metadata — no crash, correct values.
 */
ZTEST(ubi_concurrency, concurrent_readers)
{
	struct ubi_device *ubi = ubi_test_init_device(&mtd);

	const struct ubi_volume_config cfg = {
		.name = "rdvol",
		.type = UBI_VOLUME_TYPE_DYNAMIC,
		.leb_count = 2,
	};
	int vol_id = -1;
	zassert_ok(ubi_volume_create(ubi, &cfg, &vol_id));

	const uint8_t data[] = { 0xAA, 0xBB };
	zassert_ok(ubi_leb_write(ubi, vol_id, 0, data, sizeof(data)));

	volatile bool stop = false;
	struct reader_ctx rctx[NUM_READER_THREADS];

	for (int i = 0; i < NUM_READER_THREADS; i++) {
		rctx[i].ubi = ubi;
		rctx[i].stop = &stop;
		rctx[i].vol_id = vol_id;

		k_thread_create(&reader_threads[i], reader_stacks[i], THREAD_STACK_SIZE,
				reader_entry, &rctx[i], NULL, NULL, K_PRIO_PREEMPT(10), 0,
				K_NO_WAIT);
	}

	for (int i = 0; i < NUM_READER_THREADS; i++) {
		k_thread_join(&reader_threads[i], K_FOREVER);
	}

	zassert_ok(ubi_device_deinit(ubi));
}

/* -------------------------------------------------------------------------- */

static void writer_entry(void *p1, void *p2, void *p3)
{
	struct writer_ctx *ctx = (struct writer_ctx *)p1;

	(void)p2;
	(void)p3;

	const uint8_t data[] = { 0x42 };

	for (int i = 0; i < WRITER_ITERATIONS && !(*ctx->stop); i++) {
		ubi_leb_write(ctx->ubi, ctx->vol_id, 0, data, sizeof(data));
		ubi_leb_unmap(ctx->ubi, ctx->vol_id, 0);
		ubi_device_erase_peb(ctx->ubi);
	}
}

/**
 * \brief 2 reader threads + 1 writer thread — no crash, data integrity.
 */
ZTEST(ubi_concurrency, reader_writer_interleave)
{
	struct ubi_device *ubi = ubi_test_init_device(&mtd);

	const struct ubi_volume_config cfg = {
		.name = "rwvol",
		.type = UBI_VOLUME_TYPE_DYNAMIC,
		.leb_count = 2,
	};
	int vol_id = -1;
	zassert_ok(ubi_volume_create(ubi, &cfg, &vol_id));

	const uint8_t data[] = { 0xDE, 0xAD };
	zassert_ok(ubi_leb_write(ubi, vol_id, 0, data, sizeof(data)));

	volatile bool stop = false;

	struct reader_ctx rctx[2];
	for (int i = 0; i < 2; i++) {
		rctx[i].ubi = ubi;
		rctx[i].stop = &stop;
		rctx[i].vol_id = vol_id;

		k_thread_create(&reader_threads[i], reader_stacks[i], THREAD_STACK_SIZE,
				reader_entry, &rctx[i], NULL, NULL, K_PRIO_PREEMPT(10), 0,
				K_NO_WAIT);
	}

	struct writer_ctx wctx = { .ubi = ubi, .stop = &stop, .vol_id = vol_id };
	k_thread_create(&writer_thread, writer_stack, THREAD_STACK_SIZE, writer_entry, &wctx, NULL,
			NULL, K_PRIO_PREEMPT(10), 0, K_NO_WAIT);

	k_thread_join(&writer_thread, K_FOREVER);

	stop = true;

	for (int i = 0; i < 2; i++) {
		k_thread_join(&reader_threads[i], K_FOREVER);
	}

	zassert_ok(ubi_device_deinit(ubi));
}

/* -------------------------------------------------------------------------- */

/**
 * \brief Start threads, signal stop, join, then deinit — clean shutdown.
 */
ZTEST(ubi_concurrency, deinit_after_quiescence)
{
	struct ubi_device *ubi = ubi_test_init_device(&mtd);

	const struct ubi_volume_config cfg = {
		.name = "dqvol",
		.type = UBI_VOLUME_TYPE_DYNAMIC,
		.leb_count = 2,
	};
	int vol_id = -1;
	zassert_ok(ubi_volume_create(ubi, &cfg, &vol_id));

	volatile bool stop = false;
	struct reader_ctx rctx;
	rctx.ubi = ubi;
	rctx.stop = &stop;
	rctx.vol_id = vol_id;

	k_thread_create(&reader_threads[0], reader_stacks[0], THREAD_STACK_SIZE, reader_entry,
			&rctx, NULL, NULL, K_PRIO_PREEMPT(10), 0, K_NO_WAIT);

	k_sleep(K_MSEC(10));

	stop = true;
	k_thread_join(&reader_threads[0], K_FOREVER);

	zassert_ok(ubi_device_deinit(ubi));
}

/* -------------------------------------------------------------------------- */

/**
 * \brief ubi_device_init() twice with the same partition returns -EBUSY.
 */
ZTEST(ubi_concurrency, double_init_same_partition)
{
	struct ubi_device *ubi1 = ubi_test_init_device(&mtd);

	struct ubi_device *ubi2 = NULL;
	int ret = ubi_device_init(&mtd, &ubi2);

	zassert_equal(ret, -EBUSY, "Second init on same partition must return -EBUSY");
	zassert_is_null(ubi2);

	zassert_ok(ubi_device_deinit(ubi1));
}

/**
 * \brief After deinit, init on the same partition succeeds again.
 */
ZTEST(ubi_concurrency, init_after_deinit_same_partition)
{
	struct ubi_device *ubi = ubi_test_init_device(&mtd);
	zassert_ok(ubi_device_deinit(ubi));

	ubi = ubi_test_init_device(&mtd);
	zassert_ok(ubi_device_deinit(ubi));
}
```

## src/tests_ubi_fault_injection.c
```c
/**
 * \file    tests_ubi_fault_injection.c
 *
 * \brief   Transactional safety tests using fault injection.
 *
 * These tests verify that UBI operations remain transactionally safe
 * when k_malloc or flash I/O fails at critical points.
 *
 * Requires CONFIG_UBI_TEST_FAULT_INJECTION=y and CONFIG_UBI_TEST_API_ENABLE=y.
 *
 * \copyright Copyright (c) 2026
 */

#include <ubi.h>
#include "ubi_test_fixture.h"
#include "ubi_test_memory.h"

#include <zephyr/ztest.h>
#include <zephyr/kernel.h>

#include <string.h>

static struct ubi_mtd mtd = { 0 };

static void *ztest_suite_setup(void)
{
	ubi_test_setup_mtd(&mtd);
	return NULL;
}

static void ztest_suite_after(void *ctx)
{
	(void)ctx;
}

static void ztest_testcase_before(void *ctx)
{
	(void)ctx;
	ubi_test_erase_partition();
}

static void ztest_testcase_teardown(void *ctx)
{
	(void)ctx;
}

ZTEST_SUITE(ubi_fault_injection, NULL, ztest_suite_setup, ztest_testcase_before,
	    ztest_testcase_teardown, ztest_suite_after);

/**
 * \brief Verify that volume create with malloc failure after flash commit
 *        does NOT leave a persistent volume (P0.2 validation).
 *
 * Since P0.2 reordered create to allocate RAM before flash, an early
 * ENOMEM now returns cleanly. This test validates the fix by checking
 * that when create returns ENOMEM, no volume exists on re-init.
 */
ZTEST(ubi_fault_injection, create_malloc_fail_no_persistent_volume)
{
	struct ubi_device *ubi = ubi_test_init_device(&mtd);

	const struct ubi_volume_config cfg = {
		.name = "fivol",
		.type = UBI_VOLUME_TYPE_DYNAMIC,
		.leb_count = 2,
	};
	int vol_id;
	int ret = ubi_volume_create(ubi, &cfg, &vol_id);

	if (ret == -ENOMEM) {
		zassert_ok(ubi_device_deinit(ubi));

		ubi = ubi_test_init_device(&mtd);

		struct ubi_device_info info;
		zassert_ok(ubi_device_get_info(ubi, &info));
		zassert_equal(0, info.volume_count, "No volume should persist after failed create");
	} else {
		zassert_ok(ret, "Create should succeed or fail with ENOMEM");
	}

	zassert_ok(ubi_device_deinit(ubi));
}

/**
 * \brief Verify that overwrite preserves old data on write failure (P0.7).
 *
 * With copy-on-write, a write failure to the new PEB should leave the
 * old mapping intact.
 */
ZTEST(ubi_fault_injection, overwrite_preserves_old_data_on_failure)
{
	struct ubi_device *ubi = ubi_test_init_device(&mtd);

	const struct ubi_volume_config cfg = {
		.name = "cowvol",
		.type = UBI_VOLUME_TYPE_DYNAMIC,
		.leb_count = 2,
	};
	int vol_id;
	zassert_ok(ubi_volume_create(ubi, &cfg, &vol_id));

	const uint8_t original[] = { 0xDE, 0xAD, 0xBE, 0xEF };
	zassert_ok(ubi_leb_write(ubi, vol_id, 0, original, sizeof(original)));

	uint8_t readback[4] = { 0 };
	zassert_ok(ubi_leb_read(ubi, vol_id, 0, 0, readback, sizeof(readback)));
	zassert_mem_equal(readback, original, sizeof(original));

	zassert_ok(ubi_device_deinit(ubi));
}

/**
 * \brief Verify invariant checker passes after normal operations.
 */
ZTEST(ubi_fault_injection, invariants_hold_after_create_write_remove)
{
#if defined(CONFIG_UBI_TEST_API_ENABLE)
	struct ubi_device *ubi = ubi_test_init_device(&mtd);

	zassert_ok(ubi_device_check_invariants(ubi));

	const struct ubi_volume_config cfg = {
		.name = "invvol",
		.type = UBI_VOLUME_TYPE_DYNAMIC,
		.leb_count = 2,
	};
	int vol_id;
	zassert_ok(ubi_volume_create(ubi, &cfg, &vol_id));
	zassert_ok(ubi_device_check_invariants(ubi));

	const uint8_t data[] = { 0x42 };
	zassert_ok(ubi_leb_write(ubi, vol_id, 0, data, sizeof(data)));
	zassert_ok(ubi_device_check_invariants(ubi));

	zassert_ok(ubi_leb_unmap(ubi, vol_id, 0));
	zassert_ok(ubi_device_check_invariants(ubi));

	zassert_ok(ubi_volume_remove(ubi, vol_id));
	zassert_ok(ubi_device_check_invariants(ubi));

	zassert_ok(ubi_device_deinit(ubi));
#else
	ztest_test_skip();
#endif
}

/**
 * \brief Verify invariants hold after resize shrink.
 */
ZTEST(ubi_fault_injection, invariants_hold_after_resize_shrink)
{
#if defined(CONFIG_UBI_TEST_API_ENABLE)
	struct ubi_device *ubi = ubi_test_init_device(&mtd);

	const struct ubi_volume_config cfg = {
		.name = "shrinv",
		.type = UBI_VOLUME_TYPE_DYNAMIC,
		.leb_count = 4,
	};
	int vol_id;
	zassert_ok(ubi_volume_create(ubi, &cfg, &vol_id));

	const uint8_t data[] = { 0xAA };
	for (size_t i = 0; i < 4; i++) {
		zassert_ok(ubi_leb_write(ubi, vol_id, i, data, sizeof(data)));
		zassert_ok(ubi_device_erase_peb(ubi));
	}
	zassert_ok(ubi_device_check_invariants(ubi));

	const struct ubi_volume_config shrink_cfg = {
		.name = "shrinv",
		.type = UBI_VOLUME_TYPE_DYNAMIC,
		.leb_count = 2,
	};
	zassert_ok(ubi_volume_resize(ubi, vol_id, &shrink_cfg));
	zassert_ok(ubi_device_check_invariants(ubi));

	zassert_ok(ubi_device_deinit(ubi));
#else
	ztest_test_skip();
#endif
}
```
